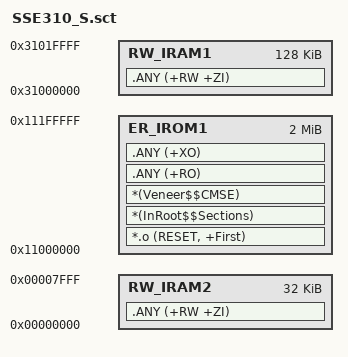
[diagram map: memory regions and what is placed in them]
; *************************************************************
; *** Scatter-Loading Description File generated by uVision ***
; *************************************************************

LR_IROM1 0x11000000 0x00200000  {    ; load region size_region
  ER_IROM1 0x11000000 0x00200000  {  ; load address = execution address
   *.o (RESET, +First)
   *(InRoot$$Sections)
   *(Veneer$$CMSE)                   ; check with partition.h
   .ANY (+RO)
   .ANY (+XO)
  }
  RW_IRAM1 0x31000000 0x00020000  {  ; RW data
   .ANY (+RW +ZI)
  }
  RW_IRAM2 0x00000000 0x00008000  {
   .ANY (+RW +ZI)
  }
}

